# soc-perf-c809403 register map
Vendor: litex
Registers are 32-bit, read-write, reset 0x0 unless marked. A register's access mark holds for its fields unless they carry their own. Offsets are from the block's base; [hi:lo] are bit positions.

## I2C
Base 0xF000E000
0x00 PRESCALE reset 0xFFFF — Prescaler value. Set to (module clock / (5 * I2C freq) - 1). Example: if module clock is equal to sysclk; syclk is 100MHz; and I2C freq is 100kHz, then prescaler is (100MHz / (5 * 100kHz) - 1) = 199. Reset value: 0xFFFF
  [15:0] prescale
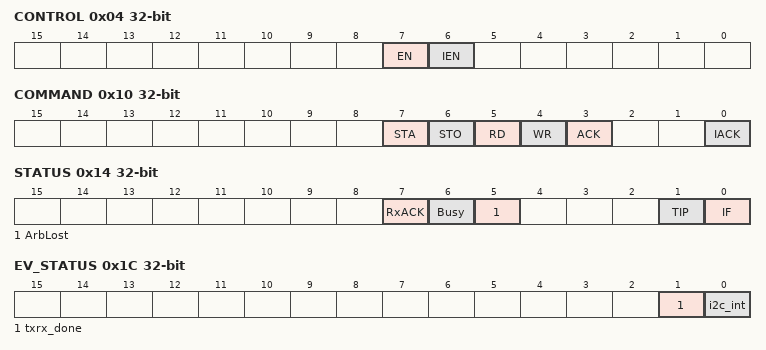
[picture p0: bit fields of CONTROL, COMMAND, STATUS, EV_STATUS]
0x04 CONTROL
  [7] EN — When set to `1`, the core is enabled.
  [6] IEN — When set to `1`, interrupts are enabled.
0x08 TXR — Next byte to transmit to slave devices. LSB indicates R/W during address phases, `1` for reading from slaves, `0` for writing to slaves
  [7:0] txr
0x0C RXR — Data being read from slaved devices
  [7:0] rxr
0x10 COMMAND
  [7] STA — generate (repeated) start condition
  [6] STO — generate stop condition
  [5] RD — read from slave
  [4] WR — write to slave
  [3] ACK — when a receiver, sent ack (`ACK=0`) or nack (`ACK=1`)
  [0] IACK — Interrupt acknowledge; when set, clears a pending interrupt
0x14 STATUS
  [7] RxACK — Received acknowledge from slave. 1 = no ack received, 0 = ack received
  [6] Busy — I2C block is busy processing the latest command
  [5] ArbLost — Set when arbitration for the bus is lost
  [1] TIP — transfer in progress
  [0] IF — Interrupt flag, This bit is set when an interrupt is pending, which will cause a processor interrupt request if the IEN bit is set. The Interrupt Flag is set upon the completion of one byte of data transfer.
0x18 CORE_RESET
  [0] reset — Write `1` for a synchronous reset of the I2C core. Does not reset the prescale value. This signal is outside of the OpenCores spec.
0x1C EV_STATUS — Triggered on the falling edge of TIP
  [1] txrx_done — Level of the ``txrx_done`` event
  [0] i2c_int — Level of the ``i2c_int`` event
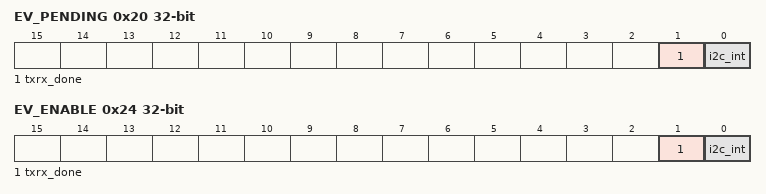
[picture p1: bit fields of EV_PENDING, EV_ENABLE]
0x20 EV_PENDING — Triggered on the falling edge of TIP
  [1] txrx_done — Triggered on the falling edge of TIP
  [0] i2c_int — Triggered when arbitration is lost or transaction done. Requires IACK write to clear or else it will re-trigger.
0x24 EV_ENABLE — Triggered on the falling edge of TIP
  [1] txrx_done — Write a ``1`` to enable the ``txrx_done`` Event
  [0] i2c_int — Write a ``1`` to enable the ``i2c_int`` Event

## BTEVENTS
Base 0xF000F000
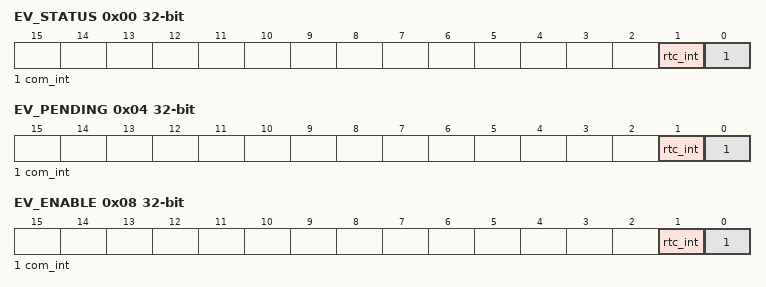
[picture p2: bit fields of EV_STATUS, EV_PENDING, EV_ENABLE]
0x00 EV_STATUS — This register contains the current raw level of the rtc_int event trigger. Writes to this register have no effect.
  [1] rtc_int — Level of the ``rtc_int`` event
  [0] com_int — Level of the ``com_int`` event
0x04 EV_PENDING — When a rtc_int event occurs, the corresponding bit will be set in this register. To clear the Event, set the corresponding bit in this register.
  [1] rtc_int — `1` if a `rtc_int` event occurred. This Event is triggered on a **falling** edge.
  [0] com_int — `1` if a `com_int` event occurred. This Event is triggered on a **falling** edge.
0x08 EV_ENABLE — This register enables the corresponding rtc_int events. Write a ``0`` to this register to disable individual events.
  [1] rtc_int — Write a ``1`` to enable the ``rtc_int`` Event
  [0] com_int — Write a ``1`` to enable the ``com_int`` Event

## MESSIBLE
Base 0xF0010000
Same registers: MESSIBLE2 0xF0011000
0x00 IN — Write half of the FIFO to send data out the Messible. Writing to this register advances the write pointer automatically.
  [7:0] in
0x04 OUT — Read half of the FIFO to receive data on the Messible. Reading from this register advances the read pointer automatically.
  [7:0] out
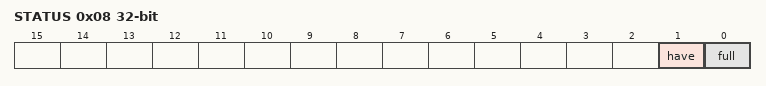
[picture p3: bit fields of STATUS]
0x08 STATUS
  [1] have — `1` if data can be read from the OUT FIFO.
  [0] full — `0` if more data can fit into the IN FIFO.

## TICKTIMER
Base 0xF0012000
0x00 CONTROL
  [0] reset — Write a `1` to this bit to reset the count to 0. This bit has priority over all other requests.
0x04 TIME1 — Bits 32-63 of `TICKTIMER_TIME`. Elapsed time in systicks
  [31:0] time
0x08 TIME0 — Bits 0-31 of `TICKTIMER_TIME`.
  [31:0] time
0x0C MSLEEP_TARGET1 — Bits 32-63 of `TICKTIMER_MSLEEP_TARGET`. Target time in 1.0ms ticks
  [31:0] msleep_target
0x10 MSLEEP_TARGET0 — Bits 0-31 of `TICKTIMER_MSLEEP_TARGET`.
  [31:0] msleep_target
0x14 EV_STATUS — This register contains the current raw level of the alarm event trigger. Writes to this register have no effect.
  [0] alarm — Level of the ``alarm`` event
0x18 EV_PENDING — When a alarm event occurs, the corresponding bit will be set in this register. To clear the Event, set the corresponding bit in this register.
  [0] alarm — `1` if a `alarm` event occurred. This Event is **level triggered** when the signal is **high**.
0x1C EV_ENABLE — This register enables the corresponding alarm events. Write a ``0`` to this register to disable individual events.
  [0] alarm — Write a ``1`` to enable the ``alarm`` Event
